# nrf5340_network register map
Vendor: Nordic Semiconductor; Series: nrf53; File version: 1
CPU: CM33 r0p4, little endian, MPU, no FPU, 3 interrupt priority bits, 30 interrupts
Registers are 32-bit, read-write, reset 0x0 unless marked. A register's access mark holds for its fields unless they carry their own. Offsets are from the block's base; [hi:lo] are bit positions; lines under a group give offsets from that group; {n}, {i} and the like mark numbered series; 'fields as' and 'values as' point back to an identical list.

## DPPIC_NS — Distributed programmable peripheral interconnect controller
Base 0x4100F000
{0x0+8i} TASKS_CHG[{i}] (i=0..5) group — Channel group tasks
  0x00 EN wo — Description cluster: Enable channel group n
    [0] EN — Enable channel group n
      1=Trigger task
  0x04 DIS wo — Description cluster: Disable channel group n
    [0] DIS — Disable channel group n
      1=Trigger task
{0x80+8i} SUBSCRIBE_CHG[{i}] (i=0..5) group — Subscribe configuration for tasks
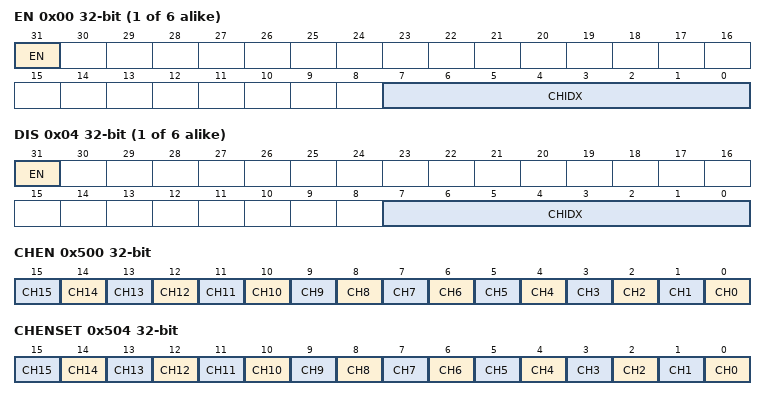
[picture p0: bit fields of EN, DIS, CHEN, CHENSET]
  0x00 EN — Description cluster: Subscribe configuration for task CHG[n].EN
    [31] EN
      0=Disabled (Disable subscription); 1=Enabled (Enable subscription)
    [7:0] CHIDX — Channel that task CHG[n].EN will subscribe to
  0x04 DIS — Description cluster: Subscribe configuration for task CHG[n].DIS
    [31] EN
      values as SUBSCRIBE_CHG[0].EN.EN
    [7:0] CHIDX — Channel that task CHG[n].DIS will subscribe to
0x500 CHEN — Channel enable register
  [all] fields
    0=Disabled (Disable channel); 1=Enabled (Enable channel)
  [n] CH{n} (n=0..15) — Enable or disable channel {n}
0x504 CHENSET write-1-sets — Channel enable set register
  [all] fields
    on read: 0=Disabled (Read: Channel disabled); 1=Enabled (Read: Channel enabled) | on write: 1=Set (Write: Enable channel)
  [n] CH{n} (n=0..15) — Channel {n} enable set register. Writing 0 has no effect.
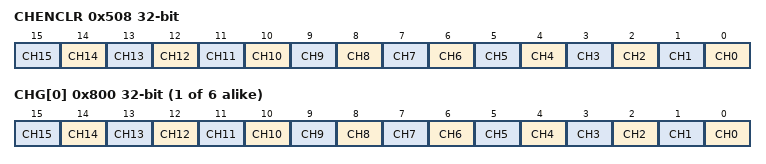
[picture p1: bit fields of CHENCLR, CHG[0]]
0x508 CHENCLR write-1-clears — Channel enable clear register
  [all] fields
    on read: 0=Disabled (Read: Channel disabled); 1=Enabled (Read: Channel enabled) | on write: 1=Clear (Write: Disable channel)
  [n] CH{n} (n=0..15) — Channel {n} enable clear register. Writing 0 has no effect.
{0x800+4i} CHG[{i}] (i=0..5) — Description collection: Channel group n Note: Writes to this register are ignored if either SUBSCRIBE_CHG[n].EN or SUBSCRIBE_CHG[n].DIS is enabled
  [all] fields
    0=Excluded; 1=Included
  [n] CH{n} (n=0..15) — Include or exclude channel {n}

## TEMP_NS — Temperature Sensor
Base 0x41010000
0x00 TASKS_START wo — Start temperature measurement
  [0] TASKS_START
    1=Trigger task
0x04 TASKS_STOP wo — Stop temperature measurement
  [0] TASKS_STOP
    1=Trigger task
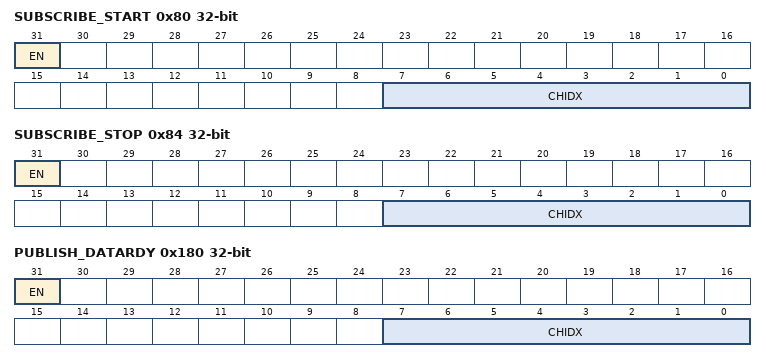
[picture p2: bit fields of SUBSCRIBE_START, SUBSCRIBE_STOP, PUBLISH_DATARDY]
0x80 SUBSCRIBE_START — Subscribe configuration for task START
  [31] EN
    0=Disabled (Disable subscription); 1=Enabled (Enable subscription)
  [7:0] CHIDX — Channel that task START will subscribe to
0x84 SUBSCRIBE_STOP — Subscribe configuration for task STOP
  [31] EN
    values as SUBSCRIBE_START.EN
  [7:0] CHIDX — Channel that task STOP will subscribe to
0x100 EVENTS_DATARDY — Temperature measurement complete, data ready
  [0] EVENTS_DATARDY
    0=NotGenerated (Event not generated); 1=Generated (Event generated)
0x180 PUBLISH_DATARDY — Publish configuration for event DATARDY
  [31] EN
    0=Disabled (Disable publishing); 1=Enabled (Enable publishing)
  [7:0] CHIDX — Channel that event DATARDY will publish to.
0x304 INTENSET — Enable interrupt
  [0] DATARDY — Write '1' to enable interrupt for event DATARDY
    on read: 0=Disabled (Read: Disabled); 1=Enabled (Read: Enabled) | on write: 1=Set (Enable)
0x308 INTENCLR — Disable interrupt
  [0] DATARDY — Write '1' to disable interrupt for event DATARDY
    on read: 0=Disabled (Read: Disabled); 1=Enabled (Read: Enabled) | on write: 1=Clear (Disable)
0x508 TEMP ro — Temperature in degC (0.25deg steps)
0x520 A0 reset 0x2D9 — Slope of 1st piece wise linear function
  [11:0] A0
0x524 A1 reset 0x322 — Slope of 2nd piece wise linear function
  [11:0] A1
0x528 A2 reset 0x355 — Slope of 3rd piece wise linear function
  [11:0] A2
0x52C A3 reset 0x3DF — Slope of 4th piece wise linear function
  [11:0] A3
0x530 A4 reset 0x44E — Slope of 5th piece wise linear function
  [11:0] A4
0x534 A5 reset 0x4B7 — Slope of 6th piece wise linear function
  [11:0] A5
0x540 B0 reset 0xFC7 — y-intercept of 1st piece wise linear function
  [11:0] B0
0x544 B1 reset 0xF71 — y-intercept of 2nd piece wise linear function
  [11:0] B1
0x548 B2 reset 0xF6C — y-intercept of 3rd piece wise linear function
  [11:0] B2
0x54C B3 reset 0xFCB — y-intercept of 4th piece wise linear function
  [11:0] B3
0x550 B4 reset 0x4B — y-intercept of 5th piece wise linear function
  [11:0] B4
0x554 B5 reset 0xF6 — y-intercept of 6th piece wise linear function
  [11:0] B5
0x560 T0 reset 0xE1 — End point of 1st piece wise linear function
  [7:0] T0
0x564 T1 reset 0xF9 — End point of 2nd piece wise linear function
  [7:0] T1
0x568 T2 reset 0x10 — End point of 3rd piece wise linear function
  [7:0] T2
0x56C T3 reset 0x26 — End point of 4th piece wise linear function
  [7:0] T3
0x570 T4 reset 0x3F — End point of 5th piece wise linear function
  [7:0] T4

## Notices in the file
Copyright (c) 2010 - 2020, Nordic Semiconductor ASA All rights reserved.
Redistribution and use in source and binary forms, with or without
modification, are permitted provided that the following conditions are met:
1. Redistributions of source code must retain the above copyright notice, this
list of conditions and the following disclaimer.
2. Redistributions in binary form must reproduce the above copyright
notice, this list of conditions and the following disclaimer in the
documentation and/or other materials provided with the distribution.
3. Neither the name of Nordic Semiconductor ASA nor the names of its
contributors may be used to endorse or promote products derived from this
software without specific prior written permission.
THIS SOFTWARE IS PROVIDED BY THE COPYRIGHT HOLDERS AND CONTRIBUTORS "AS IS"
AND ANY EXPRESS OR IMPLIED WARRANTIES, INCLUDING, BUT NOT LIMITED TO, THE
IMPLIED WARRANTIES OF MERCHANTABILITY, AND FITNESS FOR A PARTICULAR PURPOSE
ARE DISCLAIMED. IN NO EVENT SHALL NORDIC SEMICONDUCTOR ASA OR CONTRIBUTORS BE
LIABLE FOR ANY DIRECT, INDIRECT, INCIDENTAL, SPECIAL, EXEMPLARY, OR
CONSEQUENTIAL DAMAGES (INCLUDING, BUT NOT LIMITED TO, PROCUREMENT OF
SUBSTITUTE GOODS OR SERVICES; LOSS OF USE, DATA, OR PROFITS; OR BUSINESS
INTERRUPTION) HOWEVER CAUSED AND ON ANY THEORY OF LIABILITY, WHETHER IN
CONTRACT, STRICT LIABILITY, OR TORT (INCLUDING NEGLIGENCE OR OTHERWISE)
ARISING IN ANY WAY OUT OF THE USE OF THIS SOFTWARE, EVEN IF ADVISED OF THE
POSSIBILITY OF SUCH DAMAGE.
